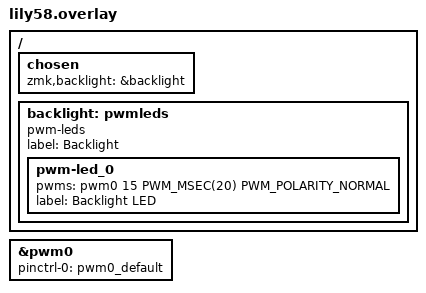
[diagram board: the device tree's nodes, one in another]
/ {
    chosen {
        zmk,backlight = &backlight;
    };

    backlight: pwmleds {
        compatible = "pwm-leds";
        label = "Backlight";
        pwm-led_0 {
            pwms = <&pwm0 15 PWM_MSEC(20) PWM_POLARITY_NORMAL>; // GPIO0.15
            label = "Backlight LED";
        };
    };
};

&pwm0 {
    status = "okay";
    pinctrl-0 = <&pwm0_default>;
    pinctrl-names = "default";
};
